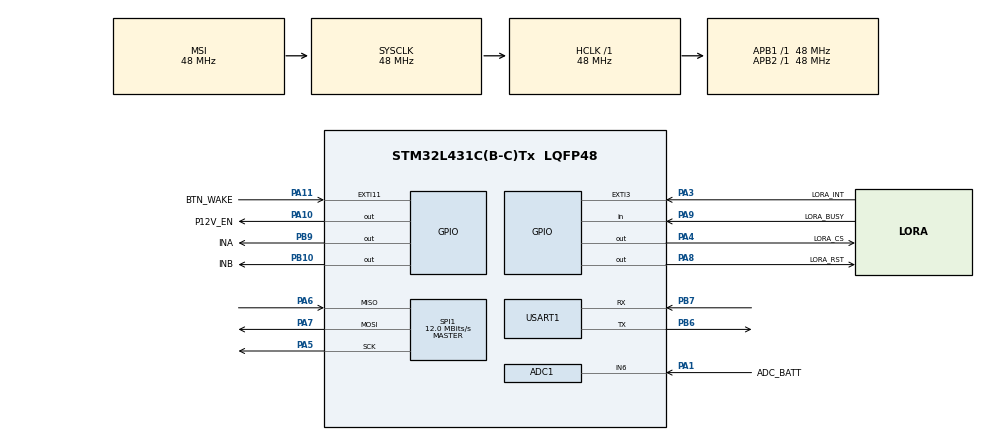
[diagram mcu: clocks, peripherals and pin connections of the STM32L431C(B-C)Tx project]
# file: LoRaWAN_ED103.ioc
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ADC1.Channel-0\#ChannelRegularConversion=ADC_CHANNEL_6
ADC1.NbrOfConversionFlag=1
ADC1.OffsetNumber-0\#ChannelRegularConversion=ADC_OFFSET_NONE
ADC1.Rank-0\#ChannelRegularConversion=1
ADC1.SamplingTime-0\#ChannelRegularConversion=ADC_SAMPLETIME_2CYCLES_5
ADC1.master=1
FREERTOS.INCLUDE_pcTaskGetTaskName=1
FREERTOS.INCLUDE_xEventGroupSetBitFromISR=1
FREERTOS.INCLUDE_xTaskAbortDelay=1
FREERTOS.INCLUDE_xTaskGetHandle=1
FREERTOS.Tasks01=defaultTask,24,128,StartDefaultTask,Default,NULL,Dynamic,NULL,NULL
FREERTOS.configCHECK_FOR_STACK_OVERFLOW=2
FREERTOS.configENABLE_FPU=1
FREERTOS.configTOTAL_HEAP_SIZE=30720
FREERTOS.configUSE_IDLE_HOOK=1
FREERTOS.configUSE_MALLOC_FAILED_HOOK=1
Mcu.Family=STM32L4
Mcu.Name=STM32L431C(B-C)Tx
Mcu.Package=LQFP48
Mcu.UserConstants=LORA_SPI,hspi1;LOG_UART,huart1;BATT_ADC,hadc1;NFC_SPI,hspi2
NVIC.EXTI15_10_IRQn=true\:5\:0\:false\:false\:true\:true\:true\:true\:true
NVIC.EXTI3_IRQn=true\:5\:0\:false\:false\:true\:true\:true\:true\:true
NVIC.PriorityGroup=NVIC_PRIORITYGROUP_4
NVIC.RTC_Alarm_IRQn=true\:5\:0\:false\:false\:true\:true\:true\:true\:true
NVIC.TIM1_UP_TIM16_IRQn=true\:15\:0\:false\:false\:true\:false\:false\:true\:true
NVIC.TimeBase=TIM1_UP_TIM16_IRQn
NVIC.TimeBaseIP=TIM1
PA1.GPIO_Label=ADC_BATT
PA1.Signal=ADCx_IN6
PA10.GPIO_Label=P12V_EN
PA10.Signal=GPIO_Output
PA11.GPIO_Label=BTN_WAKE
PA11.GPIO_ModeDefaultEXTI=GPIO_MODE_IT_FALLING
PA11.Signal=GPXTI11
PA13\ (JTMS-SWDIO).Mode=Serial_Wire
PA13\ (JTMS-SWDIO).Signal=SYS_JTMS-SWDIO
PA14\ (JTCK-SWCLK).Mode=Serial_Wire
PA14\ (JTCK-SWCLK).Signal=SYS_JTCK-SWCLK
PA3.GPIO_Label=LORA_INT
PA3.Signal=GPXTI3
PA4.GPIO_Label=LORA_CS
PA4.PinState=GPIO_PIN_SET
PA4.Signal=GPIO_Output
PA5.Mode=Full_Duplex_Master
PA5.Signal=SPI1_SCK
PA6.Mode=Full_Duplex_Master
PA6.Signal=SPI1_MISO
PA7.Mode=Full_Duplex_Master
PA7.Signal=SPI1_MOSI
PA8.GPIO_Label=LORA_RST
PA8.PinState=GPIO_PIN_SET
PA8.Signal=GPIO_Output
PA9.GPIO_Label=LORA_BUSY
PA9.Signal=GPIO_Input
PB10.GPIO_Label=INB
PB10.Signal=GPIO_Output
PB6.Mode=Asynchronous
PB6.Signal=USART1_TX
PB7.Mode=Asynchronous
PB7.Signal=USART1_RX
PB9.GPIO_Label=INA
PB9.Signal=GPIO_Output
PC14-OSC32_IN\ (PC14).Mode=LSE-External-Oscillator
PC14-OSC32_IN\ (PC14).Signal=RCC_OSC32_IN
PC15-OSC32_OUT\ (PC15).Mode=LSE-External-Oscillator
PC15-OSC32_OUT\ (PC15).Signal=RCC_OSC32_OUT
ProjectManager.HeapSize=0x200
ProjectManager.StackSize=0x400
ProjectManager.TargetToolchain=STM32CubeIDE
RCC.ADCCLockSelection=RCC_ADCCLKSOURCE_SYSCLK
RCC.ADCFreq_Value=48000000
RCC.AHBFreq_Value=48000000
RCC.APB1Freq_Value=48000000
RCC.APB1TimFreq_Value=48000000
RCC.APB2Freq_Value=48000000
RCC.APB2TimFreq_Value=48000000
RCC.CortexFreq_Value=48000000
RCC.HCLKFreq_Value=48000000
RCC.HSE_VALUE=8000000
RCC.HSI48_VALUE=48000000
RCC.HSI_VALUE=16000000
RCC.LPTIM1CLockSelection=RCC_LPTIM1CLKSOURCE_LSI
RCC.MSIClockRange=RCC_MSIRANGE_11
RCC.MSI_VALUE=48000000
RCC.PLLM=4
RCC.RTCClockSelection=RCC_RTCCLKSOURCE_LSE
RCC.SYSCLKFreq_VALUE=48000000
RCC.VCOOutputFreq_Value=96000000
RTC.Alarm-Alarm\ A=RTC_ALARM_A
RTC.AsynchPrediv=32
RTC.Format=RTC_FORMAT_BIN
RTC.SynchPrediv=1000
SH.ADCx_IN6.0=ADC1_IN6,IN6-Single-Ended
SPI1.BaudRatePrescaler=SPI_BAUDRATEPRESCALER_4
SPI1.CalculateBaudRate=12.0 MBits/s
SPI1.DataSize=SPI_DATASIZE_8BIT
SPI1.Direction=SPI_DIRECTION_2LINES
SPI1.Mode=SPI_MODE_MASTER
SPI1.VirtualType=VM_MASTER
USART1.VirtualMode-Asynchronous=VM_ASYNC
VP_FREERTOS_VS_CMSIS_V2.Mode=CMSIS_V2
VP_RTC_VS_RTC_Activate.Mode=RTC_Enabled
VP_RTC_VS_RTC_Alarm_A_Intern.Mode=Alarm A
VP_RTC_VS_RTC_Calendar.Mode=RTC_Calendar
VP_SYS_VS_tim1.Mode=TIM1
board=custom

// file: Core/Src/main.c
/* USER CODE BEGIN Header */
/**
  ******************************************************************************
  * @file           : main.c
  * @brief          : Main program body
  ******************************************************************************
  * @attention
  *
  * Copyright (c) 2024 STMicroelectronics.
  * All rights reserved.
  *
  * This software is licensed under terms that can be found in the LICENSE file
  * in the root directory of this software component.
  * If no LICENSE file comes with this software, it is provided AS-IS.
  *
  ******************************************************************************
  */
/* USER CODE END Header */
#include "main.h"
#include "cmsis_os.h"
#include "adc.h"
#include "rtc.h"
#include "spi.h"
#include "usart.h"
#include "gpio.h"

void SystemClock_Config(void);
void MX_FREERTOS_Init(void);

int main(void)
{

  /* MCU Configuration--------------------------------------------------------*/

  /* Reset of all peripherals, Initializes the Flash interface and the Systick. */
  HAL_Init();

  /* USER CODE BEGIN Init */
  extern void sys_main(void);
  sys_main();
  /* USER CODE END Init */

  /* Configure the system clock */
  SystemClock_Config();

  /* Initialize all configured peripherals */
  MX_GPIO_Init();
  MX_RTC_Init();
  MX_ADC1_Init();
  MX_SPI1_Init();
  MX_USART1_UART_Init();

  /* Init scheduler */
  osKernelInitialize();

  /* Call init function for freertos objects (in cmsis_os2.c) */
  MX_FREERTOS_Init();

  /* Start scheduler */
  osKernelStart();

  /* We should never get here as control is now taken by the scheduler */

  /* Infinite loop */
  while (1)
  {

  }
}

void SystemClock_Config(void)
{
  RCC_OscInitTypeDef RCC_OscInitStruct = {0};
  RCC_ClkInitTypeDef RCC_ClkInitStruct = {0};

  /** Configure the main internal regulator output voltage
  */
  if (HAL_PWREx_ControlVoltageScaling(PWR_REGULATOR_VOLTAGE_SCALE1) != HAL_OK)
  {
    Error_Handler();
  }

  /** Configure LSE Drive Capability
  */
  HAL_PWR_EnableBkUpAccess();
  __HAL_RCC_LSEDRIVE_CONFIG(RCC_LSEDRIVE_LOW);

  /** Initializes the RCC Oscillators according to the specified parameters
  * in the RCC_OscInitTypeDef structure.
  */
  RCC_OscInitStruct.OscillatorType = RCC_OSCILLATORTYPE_LSE|RCC_OSCILLATORTYPE_MSI;
  RCC_OscInitStruct.LSEState = RCC_LSE_ON;
  RCC_OscInitStruct.MSIState = RCC_MSI_ON;
  RCC_OscInitStruct.MSICalibrationValue = 0;
  RCC_OscInitStruct.MSIClockRange = RCC_MSIRANGE_11;
  RCC_OscInitStruct.PLL.PLLState = RCC_PLL_NONE;
  if (HAL_RCC_OscConfig(&RCC_OscInitStruct) != HAL_OK)
  {
    Error_Handler();
  }

  /** Initializes the CPU, AHB and APB buses clocks
  */
  RCC_ClkInitStruct.ClockType = RCC_CLOCKTYPE_HCLK|RCC_CLOCKTYPE_SYSCLK
                              |RCC_CLOCKTYPE_PCLK1|RCC_CLOCKTYPE_PCLK2;
  RCC_ClkInitStruct.SYSCLKSource = RCC_SYSCLKSOURCE_MSI;
  RCC_ClkInitStruct.AHBCLKDivider = RCC_SYSCLK_DIV1;
  RCC_ClkInitStruct.APB1CLKDivider = RCC_HCLK_DIV1;
  RCC_ClkInitStruct.APB2CLKDivider = RCC_HCLK_DIV1;

  if (HAL_RCC_ClockConfig(&RCC_ClkInitStruct, FLASH_LATENCY_2) != HAL_OK)
  {
    Error_Handler();
  }

  /** Enable MSI Auto calibration
  */
  HAL_RCCEx_EnableMSIPLLMode();
}

void HAL_TIM_PeriodElapsedCallback(TIM_HandleTypeDef *htim)
{
  if (htim->Instance == TIM1) {
    HAL_IncTick();
  }
}

void Error_Handler(void)
{
  __disable_irq();
  while (1)
  {
  }
}
